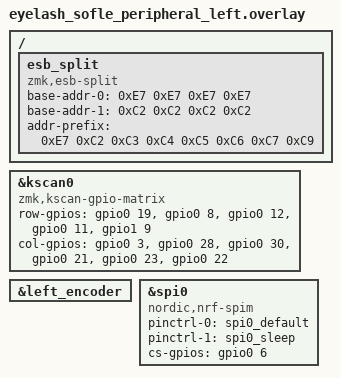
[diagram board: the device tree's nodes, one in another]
/*
*
* Copyright (c) 2021 Darryl deHaan
* SPDX-License-Identifier: MIT
*
*/

#include "eyelash_sofle.dtsi"

&kscan0 {
    compatible = "zmk,kscan-gpio-matrix";
    row-gpios
        = <&gpio0 19 (GPIO_ACTIVE_HIGH | GPIO_PULL_DOWN)>
        , <&gpio0 8 (GPIO_ACTIVE_HIGH | GPIO_PULL_DOWN)>
        , <&gpio0 12 (GPIO_ACTIVE_HIGH | GPIO_PULL_DOWN)>
        , <&gpio0 11 (GPIO_ACTIVE_HIGH | GPIO_PULL_DOWN)>
        , <&gpio1 9 (GPIO_ACTIVE_HIGH | GPIO_PULL_DOWN)>
        ;
    col-gpios
        = <&gpio0 3 GPIO_ACTIVE_HIGH>
        , <&gpio0 28 GPIO_ACTIVE_HIGH>
        , <&gpio0 30 GPIO_ACTIVE_HIGH>
        , <&gpio0 21 GPIO_ACTIVE_HIGH>
        , <&gpio0 23 GPIO_ACTIVE_HIGH>
        , <&gpio0 22 GPIO_ACTIVE_HIGH>
        ;
};

&left_encoder {
    status = "okay";
};

nice_view_spi: &spi0 {
    compatible = "nordic,nrf-spim";
    pinctrl-0 = <&spi0_default>;
    pinctrl-1 = <&spi0_sleep>;
    pinctrl-names = "default", "sleep";
    cs-gpios = <&gpio0 6 GPIO_ACTIVE_HIGH>;
};

/{
    esb_split {
        compatible = "zmk,esb-split";
        // These are arbitrary default addresses. In end user products
        // different addresses should be used for each set of devices.
        base-addr-0 = <0xE7 0xE7 0xE7 0xE7>;
        base-addr-1 = <0xC2 0xC2 0xC2 0xC2>;
        addr-prefix = <0xE7 0xC2 0xC3 0xC4 0xC5 0xC6 0xC7 0xC9>;
    };
};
